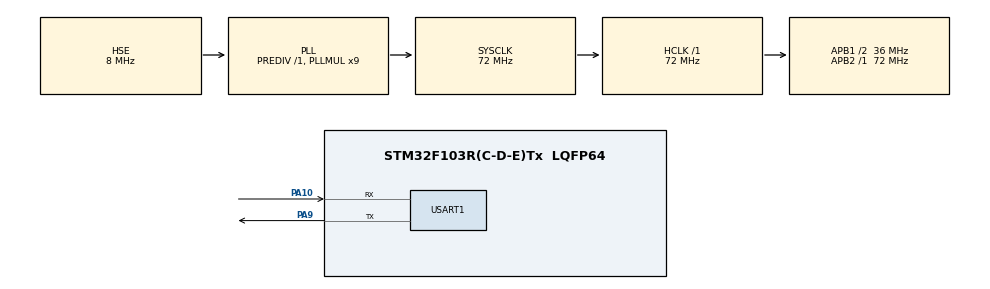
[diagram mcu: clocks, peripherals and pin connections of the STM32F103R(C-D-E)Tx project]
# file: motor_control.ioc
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Mcu.Family=STM32F1
Mcu.Name=STM32F103R(C-D-E)Tx
Mcu.Package=LQFP64
NVIC.PriorityGroup=NVIC_PRIORITYGROUP_4
NVIC.USART1_IRQn=true\:0\:0\:false\:false\:true\:true\:true\:true
PA10.Mode=Asynchronous
PA10.Signal=USART1_RX
PA13.Mode=Serial_Wire
PA13.Signal=SYS_JTMS-SWDIO
PA14.Mode=Serial_Wire
PA14.Signal=SYS_JTCK-SWCLK
PA9.Mode=Asynchronous
PA9.Signal=USART1_TX
PD0-OSC_IN.Mode=HSE-External-Oscillator
PD0-OSC_IN.Signal=RCC_OSC_IN
PD1-OSC_OUT.Mode=HSE-External-Oscillator
PD1-OSC_OUT.Signal=RCC_OSC_OUT
ProjectManager.HeapSize=0x200
ProjectManager.StackSize=0x400
ProjectManager.TargetToolchain=MDK-ARM V5.32
RCC.AHBFreq_Value=72000000
RCC.APB1CLKDivider=RCC_HCLK_DIV2
RCC.APB1Freq_Value=36000000
RCC.APB1TimFreq_Value=72000000
RCC.APB2Freq_Value=72000000
RCC.APB2TimFreq_Value=72000000
RCC.HCLKFreq_Value=72000000
RCC.PLLMUL=RCC_PLL_MUL9
RCC.PLLSourceVirtual=RCC_PLLSOURCE_HSE
RCC.SYSCLKFreq_VALUE=72000000
RCC.SYSCLKSource=RCC_SYSCLKSOURCE_PLLCLK
RCC.USBFreq_Value=72000000
USART1.VirtualMode=VM_ASYNC
board=custom

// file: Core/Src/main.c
/* USER CODE BEGIN Header */
/**
  ******************************************************************************
  * @file           : main.c
  * @brief          : Main program body
  ******************************************************************************
  * @attention
  *
  * Copyright (c) 2025 STMicroelectronics.
  * All rights reserved.
  *
  * This software is licensed under terms that can be found in the LICENSE file
  * in the root directory of this software component.
  * If no LICENSE file comes with this software, it is provided AS-IS.
  *
  ******************************************************************************
  */
/* USER CODE END Header */
#include "main.h"

/* USER CODE BEGIN Includes */
#include "bsp_dwt.h"
#include "motor_simulation.h"
#include "pid.h"
/* USER CODE END Includes */

/* USER CODE BEGIN PD */
#define KP 30
#define KI 10
#define KD 0.3
#define I_LIMIT 1

#define cut_fequency 3

#define Pi 3.141

/* USER CODE END PD */

UART_HandleTypeDef huart1;

/* USER CODE BEGIN PV */
motorObject_t Motor_v,Motor_a,Motor_a2;
pid_t PID_v,PID_a,PID_a1,PID_a2;
uint32_t DWT_CNT;
float dt, t;
float angle, velocity, angle_1, velocity_1, angle_2, velocity_2;
float input, input_1, input_2, err, err_1, err_2, tgt, prev_velo, prev_velo_1, filter_k;
/* USER CODE END PV */

void SystemClock_Config(void);
static void MX_GPIO_Init(void);
static void MX_USART1_UART_Init(void);

int main(void)
{

  /* MCU Configuration--------------------------------------------------------*/

  /* Reset of all peripherals, Initializes the Flash interface and the Systick. */
  HAL_Init();

  /* Configure the system clock */
  SystemClock_Config();

  /* Initialize all configured peripherals */
  MX_GPIO_Init();
  MX_USART1_UART_Init();
  /* USER CODE BEGIN 2 */
  DWT_Init(72);
  Motor_Object_Init(&Motor_v);
	Motor_Object_Init(&Motor_a);
	Motor_Object_Init(&Motor_a2);
	pid_init(&PID_v,60,13,1.3,10);
  pid_init(&PID_a,300,60,12.5,0.01);
	pid_init(&PID_a1,30,10,0.3,0.01);
	pid_init(&PID_a2,40,10,0.07,10);

	tgt = 0;
  //tgt = 6.282;

  /* USER CODE END 2 */

  /* Infinite loop */
  /* USER CODE BEGIN WHILE */
  while (1)
  {
    dt = DWT_GetDeltaT(&DWT_CNT);
    t += dt;

    velocity = Get_Motor_Velocity(&Motor_v);
    angle = Get_Motor_Angle(&Motor_v);

    velocity_1 = Get_Motor_Velocity(&Motor_a);
    angle_1 = Get_Motor_Angle(&Motor_a);

		velocity_2 = Get_Motor_Velocity(&Motor_a2);
    angle_2 = Get_Motor_Angle(&Motor_a2);

		filter_k=2*Pi*cut_fequency*dt;

		prev_velo=(velocity*filter_k+prev_velo*(1-filter_k));
    prev_velo_1=(velocity_2*filter_k+prev_velo_1*(1-filter_k));

    err = tgt - prev_velo;
		err_1 = tgt - angle_1;
		err_2 = tgt - angle_2;

    input = pid_calc(&PID_v,err);
		input_1 = pid_calc(&PID_a,err_1);
		input_2 = pid_calc(&PID_a2,pid_calc(&PID_a1,err_2)-prev_velo_1);

    Motor_Simulation(&Motor_v,input,dt);
		Motor_Simulation(&Motor_a,input_1,dt);
		Motor_Simulation(&Motor_a2,input_2,dt);

		tgt = 10*sin(4.5*t);
		//tgt = t;
    /* USER CODE END WHILE */

    /* USER CODE BEGIN 3 */
    HAL_Delay(1);
  }
  /* USER CODE END 3 */
}

void SystemClock_Config(void)
{
  RCC_OscInitTypeDef RCC_OscInitStruct = {0};
  RCC_ClkInitTypeDef RCC_ClkInitStruct = {0};

  /** Initializes the RCC Oscillators according to the specified parameters
  * in the RCC_OscInitTypeDef structure.
  */
  RCC_OscInitStruct.OscillatorType = RCC_OSCILLATORTYPE_HSE;
  RCC_OscInitStruct.HSEState = RCC_HSE_ON;
  RCC_OscInitStruct.HSEPredivValue = RCC_HSE_PREDIV_DIV1;
  RCC_OscInitStruct.HSIState = RCC_HSI_ON;
  RCC_OscInitStruct.PLL.PLLState = RCC_PLL_ON;
  RCC_OscInitStruct.PLL.PLLSource = RCC_PLLSOURCE_HSE;
  RCC_OscInitStruct.PLL.PLLMUL = RCC_PLL_MUL9;
  if (HAL_RCC_OscConfig(&RCC_OscInitStruct) != HAL_OK)
  {
    Error_Handler();
  }

  /** Initializes the CPU, AHB and APB buses clocks
  */
  RCC_ClkInitStruct.ClockType = RCC_CLOCKTYPE_HCLK|RCC_CLOCKTYPE_SYSCLK
                              |RCC_CLOCKTYPE_PCLK1|RCC_CLOCKTYPE_PCLK2;
  RCC_ClkInitStruct.SYSCLKSource = RCC_SYSCLKSOURCE_PLLCLK;
  RCC_ClkInitStruct.AHBCLKDivider = RCC_SYSCLK_DIV1;
  RCC_ClkInitStruct.APB1CLKDivider = RCC_HCLK_DIV2;
  RCC_ClkInitStruct.APB2CLKDivider = RCC_HCLK_DIV1;

  if (HAL_RCC_ClockConfig(&RCC_ClkInitStruct, FLASH_LATENCY_2) != HAL_OK)
  {
    Error_Handler();
  }
}

static void MX_USART1_UART_Init(void)
{

  huart1.Instance = USART1;
  huart1.Init.BaudRate = 115200;
  huart1.Init.WordLength = UART_WORDLENGTH_8B;
  huart1.Init.StopBits = UART_STOPBITS_1;
  huart1.Init.Parity = UART_PARITY_NONE;
  huart1.Init.Mode = UART_MODE_TX_RX;
  huart1.Init.HwFlowCtl = UART_HWCONTROL_NONE;
  huart1.Init.OverSampling = UART_OVERSAMPLING_16;
  if (HAL_UART_Init(&huart1) != HAL_OK)
  {
    Error_Handler();
  }

}

static void MX_GPIO_Init(void)
{

  /* GPIO Ports Clock Enable */
  __HAL_RCC_GPIOD_CLK_ENABLE();
  __HAL_RCC_GPIOA_CLK_ENABLE();

}

void Error_Handler(void)
{
  __disable_irq();
  while (1)
  {
  }
}
